AUTOSAR XML (schema 00048)
package /COM/VECTOR/CFG/WORKFLOW/SYSDESC/SYNC
  system SYSTEM: category=ECU_EXTRACT
    system mapping MAPPINGS
      data-mappings:
        data-element=COMPOSITIONTYPE.Output.HeadLight, system-signal=HeadLight
        data-element=COMPOSITIONTYPE.Input.LightSwitch, system-signal=LightSwitch
    root-software-compositions:
      root sw composition prototype COMPOSITIONTYPE: flat-map=FLATMAP, software-composition=COMPOSITIONTYPE
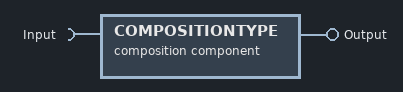
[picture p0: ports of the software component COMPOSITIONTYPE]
  composition sw component type COMPOSITIONTYPE  # UB:Derived from original system description
    provide port Output: provided-interface=Output
    require port Input: nonqueued-receiver-com-spec{data-element=LightSwitch, filter=data-filter-type=ALWAYS, init-value=0}, required-interface=Input
    10 x component:
      BswM: type=BswM
      ComM: type=ComM
      Det: type=Det
      EcuM: type=EcuM
      NvM: type=NvM
      LightCtrl: type=LightCtrl
      IoHwAb: type=IoHwAb
      BSW_Handler: type=BSW_Handler
      DemMaster_0: type=DemMaster_0
      DemSatellite_0: type=DemSatellite_0
    delegate LightCtrl.Input <-> outer port Input  # UB:Derived from original system description
    delegate LightCtrl.Output <-> outer port Output  # UB:Derived from original system description
    connect IoHwAb.LightIntensityPort -> LightCtrl.LightIntensity  # UB:Derived from original system description
    connect ComM.UR_USR_CHNL_f276589c -> BSW_Handler.ComM_UserRequest
  end to end protection set E2EPROTECTIONSET
  port interface mapping set PORTINTERFACEMAPPINGSET
